# LCD_1 register map
Vendor: Texas Instruments
Peripheral module from a debugger description file (folder msp430).
Registers are 8-bit, access not given, no defined reset value unless marked. A register's access mark holds for its fields unless they carry their own. Offsets are as the file gives them; lines under a group give offsets from that group; [hi:lo] are bit positions; {n}, {i} and the like mark numbered series; 'fields as' and 'values as' point back to an identical list; <NAME> marks a mode.

## LCD
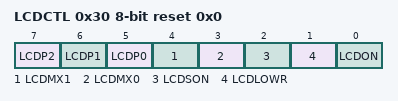
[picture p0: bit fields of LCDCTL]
0x30 LCDCTL rw reset 0x0 — LCD Control
  [7] LCDP2, [6] LCDP1, [5] LCDP0, [4] LCDMX1, [3] LCDMX0, [2] LCDSON, [1] LCDLOWR, [0] LCDON
{0x30+i} LCDM{i} (i=1..15) — LCD Memory {i}
